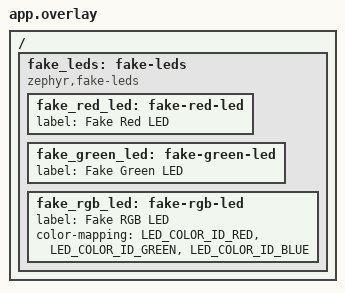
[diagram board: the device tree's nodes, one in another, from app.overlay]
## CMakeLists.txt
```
# SPDX-License-Identifier: Apache-2.0

cmake_minimum_required(VERSION 3.28.0)
find_package(Zephyr REQUIRED HINTS $ENV{ZEPHYR_BASE})
project(canopen_indicators)

target_sources(app PRIVATE src/common.c)
target_sources(app PRIVATE src/test_canopen_indicators_error_run.c)
target_sources_ifdef(CONFIG_CANOPEN_INDICATORS_MULTICOLOR_LED_SUPPORT app PRIVATE src/test_canopen_indicators_multicolor.c)
target_sources_ifdef(CONFIG_CANOPEN_INDICATORS_STATUS_LED_SUPPORT app PRIVATE src/test_canopen_indicators_status.c)
```

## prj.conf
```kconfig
CONFIG_ZTEST=y
CONFIG_CAN=y
CONFIG_CANOPEN=y
CONFIG_CANOPEN_INDICATORS=y
CONFIG_TIMING_FUNCTIONS=y
```

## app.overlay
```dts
/*
 * SPDX-FileCopyrightText: Copyright (c) 2026 Henrik Brix Andersen <henrik@brixandersen.dk>
 *
 * SPDX-License-Identifier: Apache-2.0
 */

#include <zephyr/dt-bindings/led/led.h>

/{
	fake_leds: fake-leds {
		compatible = "zephyr,fake-leds";

		fake_red_led: fake-red-led {
			label = "Fake Red LED";
		};

		fake_green_led: fake-green-led {
			label = "Fake Green LED";
		};

		fake_rgb_led: fake-rgb-led {
			label = "Fake RGB LED";
			color-mapping = <LED_COLOR_ID_RED>,
					<LED_COLOR_ID_GREEN>,
					<LED_COLOR_ID_BLUE>;
		};
	};
};
```

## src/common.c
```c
/*
 * SPDX-FileCopyrightText: Copyright (c) 2026 Henrik Brix Andersen <henrik@brixandersen.dk>
 *
 * SPDX-License-Identifier: Apache-2.0
 */

#include <string.h>

#include <zephyr/device.h>
#include <zephyr/devicetree.h>
#include <zephyr/drivers/led.h>
#include <zephyr/drivers/led/led_fake.h>
#include <zephyr/fff.h>
#include <zephyr/kernel.h>
#include <zephyr/sys/minmax.h>
#include <zephyr/types.h>
#include <zephyr/ztest.h>

#include "common.h"

const uint8_t rgb_color_red[RGB_NUM_COLORS] = {255U, 0U, 0U};
const uint8_t rgb_color_green[RGB_NUM_COLORS] = {0U, 255U, 0U};
const uint8_t rgb_color_off[RGB_NUM_COLORS] = {0U, 0U, 0U};

uint8_t rgb_color_last[RGB_NUM_COLORS];

K_SEM_DEFINE(event_sem, 0U, K_SEM_MAX_LIMIT);

const struct led_dt_spec red_led = LED_DT_SPEC_GET(DT_NODELABEL(fake_red_led));
const struct led_dt_spec green_led = LED_DT_SPEC_GET(DT_NODELABEL(fake_green_led));
const struct led_dt_spec rgb_led = LED_DT_SPEC_GET(DT_NODELABEL(fake_rgb_led));

DEFINE_FFF_GLOBALS;

int fake_led_set_brightness_delegate(const struct device *dev, uint32_t led, uint8_t value)
{
	printk("led %d brightness = %u\n", led, value);

	k_sem_give(&event_sem);

	return 0;
}

int fake_led_set_color_delegate(const struct device *dev, uint32_t led, uint8_t num_colors,
				const uint8_t *color)
{
	memcpy(rgb_color_last, color, min(sizeof(rgb_color_last), num_colors));
	k_sem_give(&event_sem);

	return 0;
}

void assert_rgb_color_set(int call_count, const uint8_t *expected)
{
	zassert_ok(k_sem_take(&event_sem, K_MSEC(TIMEOUT_MS)));
	zassert_equal(fake_led_set_color_fake.call_count, call_count);
	zassert_equal(fake_led_set_color_fake.arg0_val, rgb_led.dev);
	zassert_equal(fake_led_set_color_fake.arg1_val, rgb_led.index);
	zassert_equal(fake_led_set_color_fake.arg2_val, RGB_NUM_COLORS);
	zassert_mem_equal(rgb_color_last, expected, RGB_NUM_COLORS);
}
```

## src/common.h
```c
/*
 * SPDX-FileCopyrightText: Copyright (c) 2026 Henrik Brix Andersen <henrik@brixandersen.dk>
 *
 * SPDX-License-Identifier: Apache-2.0
 */

#ifndef TEST_CANOPEN_INDICATORS_COMMON_H_
#define TEST_CANOPEN_INDICATORS_COMMON_H_

#include <zephyr/sys/clock.h>

/* LED event timeout in milliseconds */
#define TIMEOUT_MS 2000U

/* Minimum LED pulse in nanoseconds */
#define PULSE_NS (50U * NSEC_PER_MSEC)

/* Acceptable time delta */
#define TIME_DELTA_NS (1U * NSEC_PER_MSEC)

/* Worst-case state propagation time */
#define PROPAGATION_TIME_MS 2500U

/* Number of colors of the fake RGB LED */
#define RGB_NUM_COLORS 3U

/* Fake RGB LED colors */
extern const uint8_t rgb_color_red[RGB_NUM_COLORS];
extern const uint8_t rgb_color_green[RGB_NUM_COLORS];
extern const uint8_t rgb_color_off[RGB_NUM_COLORS];

/* Last set fake RGB LED color */
extern uint8_t rgb_color_last[RGB_NUM_COLORS];

/* LED event counting semaphore */
extern struct k_sem event_sem;

/* LEDs */
extern const struct led_dt_spec red_led;
extern const struct led_dt_spec green_led;
extern const struct led_dt_spec rgb_led;

int fake_led_set_brightness_delegate(const struct device *dev, uint32_t led, uint8_t value);

int fake_led_set_color_delegate(const struct device *dev, uint32_t led, uint8_t num_colors,
				const uint8_t *color);

void assert_rgb_color_set(int call_count, const uint8_t *expected);

#endif /* TEST_CANOPEN_INDICATORS_COMMON_H_ */
```

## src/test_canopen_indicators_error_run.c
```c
/*
 * SPDX-FileCopyrightText: Copyright (c) 2026 Henrik Brix Andersen <henrik@brixandersen.dk>
 *
 * SPDX-License-Identifier: Apache-2.0
 */

#include <zephyr/canbus/canopen/indicators.h>
#include <zephyr/device.h>
#include <zephyr/drivers/led.h>
#include <zephyr/drivers/led/led_fake.h>
#include <zephyr/fff.h>
#include <zephyr/timing/timing.h>
#include <zephyr/ztest.h>

#include "common.h"

/* Global variables */
static struct canopen_indicators dut;

static void test_on_off(enum canopen_indicators_led_color color, const struct led_dt_spec *led)
{
	/* Turn LED on */
	zassert_ok(canopen_indicators_set_led_state(&dut, color, CANOPEN_INDICATORS_LED_STATE_ON));

	zassert_ok(k_sem_take(&event_sem, K_MSEC(TIMEOUT_MS)));
	zassert_equal(fake_led_set_brightness_fake.call_count, 1);
	zassert_equal(fake_led_set_brightness_fake.arg0_val, led->dev);
	zassert_equal(fake_led_set_brightness_fake.arg1_val, led->index);
	zassert_equal(fake_led_set_brightness_fake.arg2_val, LED_BRIGHTNESS_MAX);

	/* Turn LED off */
	zassert_ok(canopen_indicators_set_led_state(&dut, color, CANOPEN_INDICATORS_LED_STATE_OFF));

	zassert_ok(k_sem_take(&event_sem, K_MSEC(TIMEOUT_MS)));
	zassert_equal(fake_led_set_brightness_fake.call_count, 2);
	zassert_equal(fake_led_set_brightness_fake.arg0_val, led->dev);
	zassert_equal(fake_led_set_brightness_fake.arg1_val, led->index);
	zassert_equal(fake_led_set_brightness_fake.arg2_val, 0U);
}

ZTEST(canopen_indicators_error_run, test_red_on_off)
{
	test_on_off(CANOPEN_INDICATORS_LED_COLOR_RED, &red_led);
}

ZTEST(canopen_indicators_error_run, test_green_on_off)
{
	test_on_off(CANOPEN_INDICATORS_LED_COLOR_GREEN, &green_led);
}

static void test_isophase(enum canopen_indicators_led_color color, const struct led_dt_spec *led,
			  enum canopen_indicators_led_state state, uint64_t pulse_ns)
{
	const int events = 10;
	timing_t start_time;
	timing_t end_time;
	uint64_t total_cycles;
	uint64_t total_ns;
	int i;

	start_time = timing_counter_get();
	zassert_ok(canopen_indicators_set_led_state(&dut, color, state));

	for (i = 0; i < events; i++) {
		zassert_ok(k_sem_take(&event_sem, K_MSEC(TIMEOUT_MS)));
		end_time = timing_counter_get();

		total_cycles = timing_cycles_get(&start_time, &end_time);
		total_ns = timing_cycles_to_ns(total_cycles);

		start_time = timing_counter_get();

		TC_PRINT("total_ns = %llu\n", total_ns);

		/* Ignore first event as it may happen sooner/later than a full pulse width */
		if (i != 0) {
			zassert_within(total_ns, pulse_ns, TIME_DELTA_NS);
		}
	}

	for (i = 0; i < events; i++) {
		zassert_equal_ptr(fff.call_history[i], fake_led_set_brightness);
		zassert_equal(fake_led_set_brightness_fake.arg0_history[i], led->dev);
		zassert_equal(fake_led_set_brightness_fake.arg1_history[i], led->index);

		if (i % 2 == 0) {
			zassert_equal(fake_led_set_brightness_fake.arg2_history[i],
				      LED_BRIGHTNESS_MAX);
		} else {
			zassert_equal(fake_led_set_brightness_fake.arg2_history[i], 0U);
		}
	}
}

ZTEST(canopen_indicators_error_run, test_red_flickering)
{
	test_isophase(CANOPEN_INDICATORS_LED_COLOR_RED, &red_led,
		      CANOPEN_INDICATORS_LED_STATE_FLICKERING, PULSE_NS);
}

ZTEST(canopen_indicators_error_run, test_green_flickering)
{
	test_isophase(CANOPEN_INDICATORS_LED_COLOR_GREEN, &green_led,
		      CANOPEN_INDICATORS_LED_STATE_FLICKERING, PULSE_NS);
}

ZTEST(canopen_indicators_error_run, test_red_blinking)
{
	test_isophase(CANOPEN_INDICATORS_LED_COLOR_RED, &red_led,
		      CANOPEN_INDICATORS_LED_STATE_BLINKING, PULSE_NS * 4U);
}

ZTEST(canopen_indicators_error_run, test_green_blinking)
{
	test_isophase(CANOPEN_INDICATORS_LED_COLOR_GREEN, &green_led,
		      CANOPEN_INDICATORS_LED_STATE_BLINKING, PULSE_NS * 4U);
}

static void test_flash(enum canopen_indicators_led_color color, const struct led_dt_spec *led,
		       enum canopen_indicators_led_state state, uint8_t flashes)
{
	const int events = flashes * 4 + 1;
	timing_t start_time;
	timing_t end_time;
	uint64_t total_cycles;
	uint64_t total_ns;
	int i;

	start_time = timing_counter_get();
	zassert_ok(canopen_indicators_set_led_state(&dut, color, state));

	/* TODO: synchronize to shift registers */

	for (i = 0; i < events; i++) {
		zassert_ok(k_sem_take(&event_sem, K_MSEC(TIMEOUT_MS)));
		end_time = timing_counter_get();

		total_cycles = timing_cycles_get(&start_time, &end_time);
		total_ns = timing_cycles_to_ns(total_cycles);

		start_time = timing_counter_get();

		TC_PRINT("total_ns = %llu\n", total_ns);

		/* Ignore first event as it may happen sooner/later than a full pulse width */
		if (i != 0) {
			/* TODO: validate timing */
			/* zassert_within(total_ns, pulse_ns, TIME_DELTA_NS); */
		}
	}

	for (i = 0; i < events; i++) {
		zassert_equal_ptr(fff.call_history[i], fake_led_set_brightness);
		zassert_equal(fake_led_set_brightness_fake.arg0_history[i], led->dev);
		zassert_equal(fake_led_set_brightness_fake.arg1_history[i], led->index);

		if (i % 2 == 0) {
			zassert_equal(fake_led_set_brightness_fake.arg2_history[i],
				      LED_BRIGHTNESS_MAX);
		} else {
			zassert_equal(fake_led_set_brightness_fake.arg2_history[i], 0U);
		}
	}
}

ZTEST(canopen_indicators_error_run, test_red_single_flash)
{
	test_flash(CANOPEN_INDICATORS_LED_COLOR_RED, &red_led,
		   CANOPEN_INDICATORS_LED_STATE_SINGLE_FLASH, 1U);
}

ZTEST(canopen_indicators_error_run, test_green_single_flash)
{
	test_flash(CANOPEN_INDICATORS_LED_COLOR_GREEN, &green_led,
		   CANOPEN_INDICATORS_LED_STATE_SINGLE_FLASH, 1U);
}

ZTEST(canopen_indicators_error_run, test_red_double_flash)
{
	test_flash(CANOPEN_INDICATORS_LED_COLOR_RED, &red_led,
		   CANOPEN_INDICATORS_LED_STATE_DOUBLE_FLASH, 2U);
}

ZTEST(canopen_indicators_error_run, test_green_double_flash)
{
	test_flash(CANOPEN_INDICATORS_LED_COLOR_GREEN, &green_led,
		   CANOPEN_INDICATORS_LED_STATE_DOUBLE_FLASH, 2U);
}

ZTEST(canopen_indicators_error_run, test_red_triple_flash)
{
	test_flash(CANOPEN_INDICATORS_LED_COLOR_RED, &red_led,
		   CANOPEN_INDICATORS_LED_STATE_TRIPLE_FLASH, 3U);
}

ZTEST(canopen_indicators_error_run, test_green_triple_flash)
{
	test_flash(CANOPEN_INDICATORS_LED_COLOR_GREEN, &green_led,
		   CANOPEN_INDICATORS_LED_STATE_TRIPLE_FLASH, 3U);
}

ZTEST(canopen_indicators_error_run, test_red_quadruple_flash)
{
	test_flash(CANOPEN_INDICATORS_LED_COLOR_RED, &red_led,
		   CANOPEN_INDICATORS_LED_STATE_QUADRUPLE_FLASH, 4U);
}

ZTEST(canopen_indicators_error_run, test_green_quadruple_flash)
{
	test_flash(CANOPEN_INDICATORS_LED_COLOR_GREEN, &green_led,
		   CANOPEN_INDICATORS_LED_STATE_QUADRUPLE_FLASH, 4U);
}

static void canopen_indicators_error_run_before(void *fixture)
{
	ARG_UNUSED(fixture);

	/* Reset events counter */
	k_sem_reset(&event_sem);

	/* Reset FFF history */
	FFF_RESET_HISTORY();

	/* Re-install custom delegate */
	fake_led_set_brightness_fake.custom_fake = fake_led_set_brightness_delegate;

	/* Initialise and start timing */
	timing_init();
	timing_start();
}

static void canopen_indicators_error_run_after(void *fixture)
{
	ARG_UNUSED(fixture);

	/* Turn LEDs off */
	zassert_ok(canopen_indicators_set_led_state_red(&dut, CANOPEN_INDICATORS_LED_STATE_OFF));
	zassert_ok(canopen_indicators_set_led_state_green(&dut, CANOPEN_INDICATORS_LED_STATE_OFF));

	/* Allow state to propagate */
	k_sleep(K_MSEC(PROPAGATION_TIME_MS));

	/* Start timing */
	timing_stop();
}

static void *canopen_indicators_error_run_setup(void)
{
	zassert_true(led_is_ready_dt(&red_led));
	zassert_true(led_is_ready_dt(&green_led));

	zassert_ok(canopen_indicators_init(&dut, &k_sys_work_q, &red_led, &green_led));
	zassert_ok(canopen_indicators_enable(&dut));

	return NULL;
}

ZTEST_SUITE(canopen_indicators_error_run, NULL, canopen_indicators_error_run_setup,
	    canopen_indicators_error_run_before, canopen_indicators_error_run_after, NULL);
```

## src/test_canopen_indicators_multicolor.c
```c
/*
 * SPDX-FileCopyrightText: Copyright (c) 2026 Henrik Brix Andersen <henrik@brixandersen.dk>
 *
 * SPDX-License-Identifier: Apache-2.0
 */

#include <zephyr/canbus/canopen/indicators.h>
#include <zephyr/device.h>
#include <zephyr/drivers/led.h>
#include <zephyr/drivers/led/led_fake.h>
#include <zephyr/fff.h>
#include <zephyr/ztest.h>

#include "common.h"

/* Global variables */
static struct canopen_indicators dut;

ZTEST(canopen_indicators_multicolor, test_red_on_off)
{
	/* Turn LED on */
	zassert_ok(canopen_indicators_set_led_state_red(&dut, CANOPEN_INDICATORS_LED_STATE_ON));

	zassert_ok(k_sem_take(&event_sem, K_MSEC(TIMEOUT_MS)));
	zassert_equal(fake_led_set_brightness_fake.call_count, 1);
	zassert_equal(fake_led_set_brightness_fake.arg0_val, red_led.dev);
	zassert_equal(fake_led_set_brightness_fake.arg1_val, red_led.index);
	zassert_equal(fake_led_set_brightness_fake.arg2_val, LED_BRIGHTNESS_MAX);

	/* Turn LED off */
	zassert_ok(canopen_indicators_set_led_state_red(&dut, CANOPEN_INDICATORS_LED_STATE_OFF));

	zassert_ok(k_sem_take(&event_sem, K_MSEC(TIMEOUT_MS)));
	zassert_equal(fake_led_set_brightness_fake.call_count, 2);
	zassert_equal(fake_led_set_brightness_fake.arg0_val, red_led.dev);
	zassert_equal(fake_led_set_brightness_fake.arg1_val, red_led.index);
	zassert_equal(fake_led_set_brightness_fake.arg2_val, 0U);
}

ZTEST(canopen_indicators_multicolor, test_green_on_off)
{
	/* Turn LED on */
	zassert_ok(canopen_indicators_set_led_state_green(&dut, CANOPEN_INDICATORS_LED_STATE_ON));
	assert_rgb_color_set(1, rgb_color_green);

	/* Turn LED off */
	zassert_ok(canopen_indicators_set_led_state_green(&dut, CANOPEN_INDICATORS_LED_STATE_OFF));
	assert_rgb_color_set(2, rgb_color_off);
}

static void canopen_indicators_multicolor_before(void *fixture)
{
	ARG_UNUSED(fixture);

	/* Reset events counter */
	k_sem_reset(&event_sem);

	/* Clear last set color */
	memset(rgb_color_last, 0, sizeof(rgb_color_last));

	/* Reset FFF history */
	FFF_RESET_HISTORY();

	/* Re-install custom delegates */
	fake_led_set_brightness_fake.custom_fake = fake_led_set_brightness_delegate;
	fake_led_set_color_fake.custom_fake = fake_led_set_color_delegate;
}

static void canopen_indicators_multicolor_after(void *fixture)
{
	ARG_UNUSED(fixture);

	/* Turn LEDs off */
	zassert_ok(canopen_indicators_set_led_state_red(&dut, CANOPEN_INDICATORS_LED_STATE_OFF));
	zassert_ok(canopen_indicators_set_led_state_green(&dut, CANOPEN_INDICATORS_LED_STATE_OFF));

	/* Allow state to propagate */
	k_sleep(K_MSEC(PROPAGATION_TIME_MS));
}

static void *canopen_indicators_multicolor_setup(void)
{
	zassert_true(led_is_ready_dt(&red_led));
	zassert_true(led_is_ready_dt(&rgb_led));

	zassert_ok(canopen_indicators_init(&dut, &k_sys_work_q, &red_led, &rgb_led));
	zassert_ok(canopen_indicators_enable(&dut));

	return NULL;
}

ZTEST_SUITE(canopen_indicators_multicolor, NULL, canopen_indicators_multicolor_setup,
	    canopen_indicators_multicolor_before, canopen_indicators_multicolor_after, NULL);
```

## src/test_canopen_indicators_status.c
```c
/*
 * SPDX-FileCopyrightText: Copyright (c) 2026 Henrik Brix Andersen <henrik@brixandersen.dk>
 *
 * SPDX-License-Identifier: Apache-2.0
 */

#include <zephyr/canbus/canopen/indicators.h>
#include <zephyr/device.h>
#include <zephyr/drivers/led.h>
#include <zephyr/drivers/led/led_fake.h>
#include <zephyr/fff.h>
#include <zephyr/sys/minmax.h>
#include <zephyr/ztest.h>

#include "common.h"

/* Global variables */
static struct canopen_indicators dut;

static void test_on_off(enum canopen_indicators_led_color color, const uint8_t *expected)
{
	/* Turn LED on */
	zassert_ok(canopen_indicators_set_led_state(&dut, color, CANOPEN_INDICATORS_LED_STATE_ON));
	assert_rgb_color_set(1, expected);

	/* Turn LED off */
	zassert_ok(canopen_indicators_set_led_state(&dut, color, CANOPEN_INDICATORS_LED_STATE_OFF));
	assert_rgb_color_set(2, rgb_color_off);
}

ZTEST(canopen_indicators_status, test_red_on_off)
{
	test_on_off(CANOPEN_INDICATORS_LED_COLOR_RED, rgb_color_red);
}

ZTEST(canopen_indicators_status, test_green_on_off)
{
	test_on_off(CANOPEN_INDICATORS_LED_COLOR_GREEN, rgb_color_green);
}

ZTEST(canopen_indicators_status, test_red_priority)
{
	/* Turn green LED on */
	zassert_ok(canopen_indicators_set_led_state_green(&dut, CANOPEN_INDICATORS_LED_STATE_ON));
	assert_rgb_color_set(1, rgb_color_green);

	/* Turn red LED on, red will take priority */
	zassert_ok(canopen_indicators_set_led_state_red(&dut, CANOPEN_INDICATORS_LED_STATE_ON));
	assert_rgb_color_set(2, rgb_color_red);

	/* Turn red LED off, green back on */
	zassert_ok(canopen_indicators_set_led_state_red(&dut, CANOPEN_INDICATORS_LED_STATE_OFF));
	assert_rgb_color_set(3, rgb_color_green);

	/* Turn green LED off, both off */
	zassert_ok(canopen_indicators_set_led_state_green(&dut, CANOPEN_INDICATORS_LED_STATE_OFF));
	assert_rgb_color_set(4, rgb_color_off);

	/* Turn red LED on */
	zassert_ok(canopen_indicators_set_led_state_red(&dut, CANOPEN_INDICATORS_LED_STATE_ON));
	assert_rgb_color_set(5, rgb_color_red);

	/* Turn green LED on, red still has priority */
	zassert_ok(canopen_indicators_set_led_state_green(&dut, CANOPEN_INDICATORS_LED_STATE_ON));
	zassert_not_ok(k_sem_take(&event_sem, K_MSEC(TIMEOUT_MS)));

	/* Turn red LED off, green now on */
	zassert_ok(canopen_indicators_set_led_state_red(&dut, CANOPEN_INDICATORS_LED_STATE_OFF));
	assert_rgb_color_set(6, rgb_color_green);
}

ZTEST(canopen_indicators_status, test_biphase)
{
	/* TODO: test biphase pattern */
}

static void canopen_indicators_status_before(void *fixture)
{
	ARG_UNUSED(fixture);

	/* Reset events counter */
	k_sem_reset(&event_sem);

	/* Clear last set color */
	memset(rgb_color_last, 0, sizeof(rgb_color_last));

	/* Reset FFF history */
	FFF_RESET_HISTORY();

	/* Re-install custom delegate */
	fake_led_set_color_fake.custom_fake = fake_led_set_color_delegate;
}

static void canopen_indicators_status_after(void *fixture)
{
	ARG_UNUSED(fixture);

	/* Turn LEDs off */
	zassert_ok(canopen_indicators_set_led_state_red(&dut, CANOPEN_INDICATORS_LED_STATE_OFF));
	zassert_ok(canopen_indicators_set_led_state_green(&dut, CANOPEN_INDICATORS_LED_STATE_OFF));

	/* Allow state to propagate */
	k_sleep(K_MSEC(PROPAGATION_TIME_MS));
}

static void *canopen_indicators_status_setup(void)
{
	zassert_true(led_is_ready_dt(&rgb_led));

	zassert_ok(canopen_indicators_init(&dut, &k_sys_work_q, &rgb_led, &rgb_led));
	zassert_ok(canopen_indicators_enable(&dut));

	return NULL;
}

ZTEST_SUITE(canopen_indicators_status, NULL, canopen_indicators_status_setup,
	    canopen_indicators_status_before, canopen_indicators_status_after, NULL);
```
